# ISD9300_v3 register map
File version: 1.0
Registers are 32-bit, read-write, reset 0x0 unless marked. A register's access mark holds for its fields unless they carry their own. Offsets are from the block's base; [hi:lo] are bit positions; 'fields as' and 'values as' point back to an identical list.

## ADC — ADC Register Map
Base 0x400E0000
0x00 ADC_DAT ro (reset mask 0xFFFF0000) — ADC FIFO Data Out
  [15:0] RESULT — ADC Audio Data FIFO Read. A read of this register will read data from the audio FIFO and increment the read pointer. A read past empty will repeat the last data. Can be used with FIFOINTLV interrupt to determine if valid data is present in FIFO.
0x04 ADC_CHEN — ADC Enable Register
  [0] CHEN — ADC Enable
    0=Conversion stopped and ADC is reset including FIFO pointers; 1=ADC Conversion enabled
0x08 ADC_CLKDIV — ADC Clock Divider Register
  [7:0] CLKDIV — ADC Clock Divider. This register determines the clock division ration between the incoming ADC_CLK ( aaa HCLK by default) and the Delta-Sigma sampling clock of the ADC. This together with the over-sampling ratio (OVSPLRAT) determines the audio sample rate of the converter. CLKDIV should be set to give a SDCLK frequency in the range of 1.024-6.144MHz. CLKDIV must be greater than 2. SDCLK frequency aaa HCLK ÷ CLKDIV
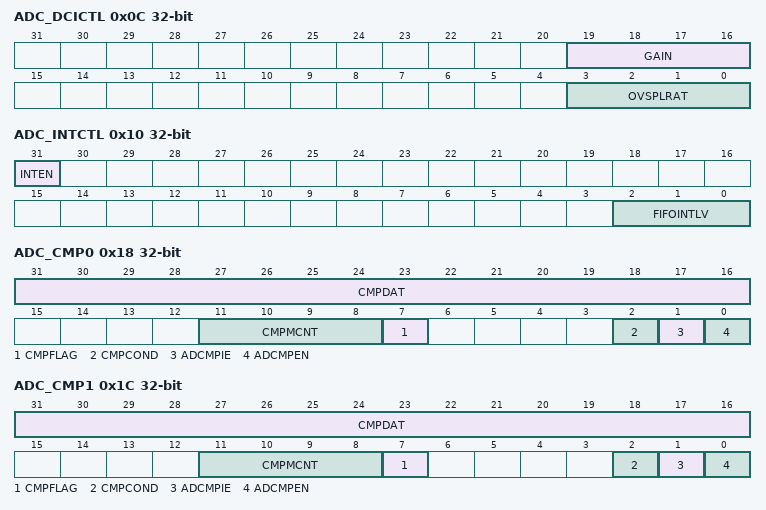
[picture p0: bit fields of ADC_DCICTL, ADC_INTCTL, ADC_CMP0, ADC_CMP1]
0x0C ADC_DCICTL — ADC Decimation Control Register
  [19:16] GAIN — CIC Filter Additional Gain. This should normally remain default 0. Can be set to non-zero values to provide additional digital gain from the decimation filter. An additional gain is applied to signal of GAIN÷2.
  [3:0] OVSPLRAT — Decimation Over-Sampling Ratio. This term determines the over-sampling ratio of the decimation filter. Valid values are: 0: OVSPLRAT aaa 64. 1: OVSPLRAT aaa 128. 2: OVSPLRAT aaa 192. 3: OVSPLRAT aaa 384
0x10 ADC_INTCTL — ADC Interrupt Control Register
  [31] INTEN — Interrupt Enable. If set to '1' an interrupt is generated whenever FIFO level exceeds that set in FIFOINTLV.
  [2:0] FIFOINTLV — FIFO Interrupt Level. Determines at what level the ADC FIFO will generate a servicing interrupt to the CPU. Interrupt will be generated when number of words present in ADC FIFO is > FIFOINTLV.
0x14 ADC_PDMACTL — ADC PDMA Control Register
  [0] RXDMAEN — Enable ADC PDMA Receive Channel. Enable ADC PDMA. If set, then ADC will request PDMA service when data is available.
0x18 ADC_CMP0 — ADC Comparator 0 Control Register
  [31:16] CMPDAT — Comparison Data. 16 bit value to compare to FIFO output word.
  [11:8] CMPMCNT — Compare Match Count. When the A/D FIFO result matches the compare condition defined by CMPCOND, the internal match counter will increase by 1. When the internal counter reaches the value to (CMPMCNT +1), the CMPFLAG bit will be set.
  [7] CMPFLAG — Compare Flag. When the conversion result meets condition in ADCMPR0 this bit is set to 1. It is cleared by writing 1 to self.
  [2] CMPCOND — Compare Condition. Note: When the internal counter reaches the value (CMPMCNT +1), the CMPFLAG bit will be set.
    0=Set the compare condition that result is less than CMPDAT; 1=Set the compare condition that result is greater or equal to CMPDAT
  [1] ADCMPIE — Compare Interrupt Enable. If the compare function is enabled and the compare condition matches the setting of CMPCOND and CMPMCNT, CMPFLAG bit will be asserted, if ADCMPIE is set to 1, a compare interrupt request is generated.
    0=Disable compare function interrupt; 1=Enable compare function interrupt
  [0] ADCMPEN — Compare Enable. Set this bit to 1 to enable compare CMPDAT with FIFO data output.
    0=Disable compare; 1=Enable compare
0x1C ADC_CMP1 — ADC Comparator 0 Control Register
  fields as ADC_CMP0

## DPWM — DPWM Register Map
Base 0x40070000
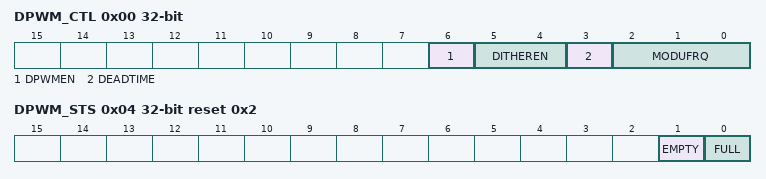
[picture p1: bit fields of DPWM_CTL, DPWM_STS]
0x00 DPWM_CTL — DPWM Control Register
  [6] DPWMEN — DPWM Enable
    0=Disable DPWM, SPK pins are tri-state, CIC filter is reset, FIFO pointers are reset (FIFO data is not reset); 1=Enable DPWM, SPK pins are enabled and driven, data is taken from FIFO
  [5:4] DITHEREN — DPWM Signal Dither Control. To prevent structured noise on PWM output due to DC offsets in the input signal it is possible to add random dither to the PWM signal. These bits control the dither:
    0=No dither; 1=+/- 1 bit dither; 3=+/- 2 bit dither
  [3] DEADTIME — DPWM Driver Deadtime Control. Enabling this bit will insert an additional clock cycle deadtime into the switching of PMOS and NMOS driver transistors.
  [2:0] MODUFRQ — DPWM Modulation Frequency. This parameter controls the carrier modulation frequency of the PWM signal as a proportion of DPWM_CLK. MODUFRQ : DPWM_CLK Division : Frequency for DPWM_CLK aaa 98.304MHZ. 0 : 228 : 431158. 1 : 156 : 630154. 2 : 76 : 1293474. 3 : 52 : 1890462. 4 : 780 : 126031. 5 : 524 : 187603. 6 : 396 : 248242. 7 : 268 : 366806
0x04 DPWM_STS ro reset 0x2 — DPWM DATA FIFO Status Register
  [1] EMPTY — FIFO Empty
    0=FIFO is not empty; 1=FIFO is empty
  [0] FULL — FIFO Full
    0=FIFO is not full; 1=FIFO is full
0x08 DPWM_DMACTL — DPWM PDMA Control Register
  [0] DMAEN — Enable DPWM DMA Interface
    0=Disable PDMA. No requests will be made to PDMA controller; 1=Enable PDMA. Block will request data from PDMA controller whenever FIFO is not empty
0x0C DPWM_DATA wo — DPWM DATA FIFO Input
  [15:0] INDATA — DPWM FIFO Audio Data Input. A write to this register pushes data onto the DPWM FIFO and increments the write pointer. This is the address that PDMA writes audio data to.
0x10 DPWM_ZOHDIV reset 0x30 — DPWM Zero Order Hold Division Register
  [7:0] ZOHDIV — DPWM Zero Order Hold, Down-Sampling Divisor. The input sample rate of the DPWM is set by HCLK frequency and the divisor set in this register by the following formula: Fs aaa HCLK/ZOHDIV/64. Valid range is 1 to 255. Default is 48, which gives a sample rate of 16kHz for a 49.152MHz (default) HCLK.
